VERSION ""

NS_ :

BS_:

BU_: data_logger drive_controller kart_machine_manager motec_ecu

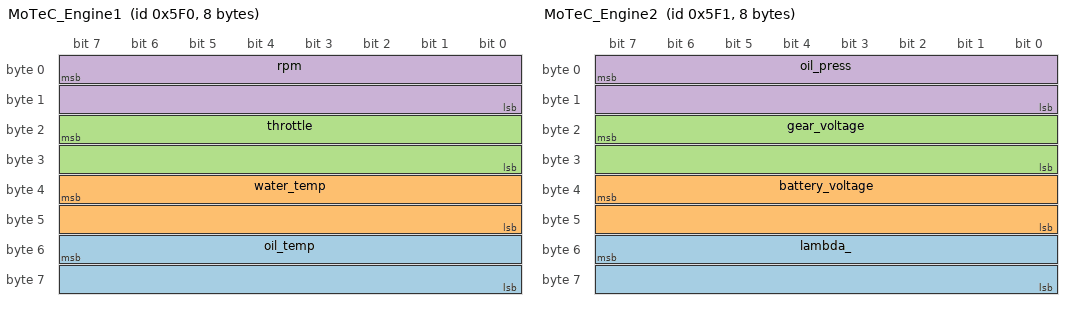
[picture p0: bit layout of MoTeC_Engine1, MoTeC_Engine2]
BO_ 1520 MoTeC_Engine1: 8 motec_ecu
 SG_ oil_temp : 55|16@0+ (0.1,0) [0|0] "degC"  kart_machine_manager
 SG_ water_temp : 39|16@0+ (0.1,0) [0|0] "degC"  kart_machine_manager
 SG_ throttle : 23|16@0+ (0.1,0) [0|0] "%"  kart_machine_manager
 SG_ rpm : 7|16@0+ (1,0) [0|0] "rpm"  kart_machine_manager

BO_ 1521 MoTeC_Engine2: 8 motec_ecu
 SG_ lambda_ : 55|16@0+ (0.001,0) [0|0] ""  kart_machine_manager
 SG_ battery_voltage : 39|16@0+ (0.01,0) [0|0] "V"  kart_machine_manager
 SG_ gear_voltage : 23|16@0+ (0.001,0) [0|0] "V"  kart_machine_manager
 SG_ oil_press : 7|16@0+ (0.1,0) [0|0] ""  kart_machine_manager

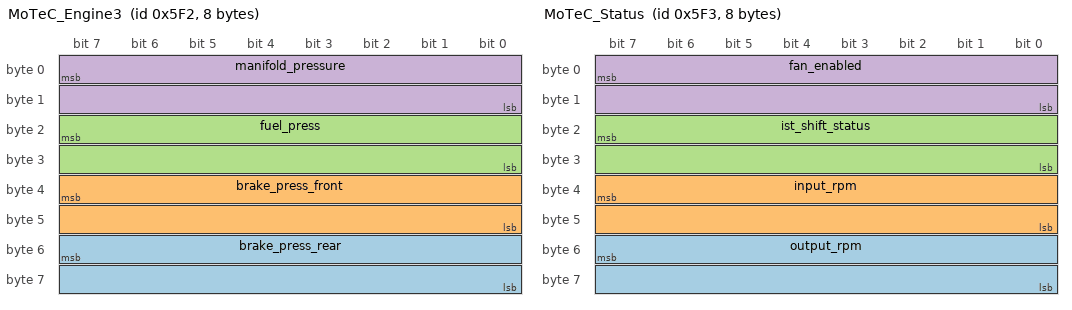
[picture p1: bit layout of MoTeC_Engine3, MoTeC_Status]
BO_ 1522 MoTeC_Engine3: 8 motec_ecu
 SG_ brake_press_rear : 55|16@0+ (0.1,0) [0|0] ""  kart_machine_manager
 SG_ brake_press_front : 39|16@0+ (0.1,0) [0|0] ""  kart_machine_manager
 SG_ fuel_press : 23|16@0+ (0.1,0) [0|0] ""  kart_machine_manager
 SG_ manifold_pressure : 7|16@0+ (0.1,0) [0|0] "kPa"  kart_machine_manager

BO_ 1523 MoTeC_Status: 8 motec_ecu
 SG_ output_rpm : 55|16@0+ (1,0) [0|0] "rpm"  kart_machine_manager
 SG_ input_rpm : 39|16@0+ (1,0) [0|0] "rpm"  kart_machine_manager
 SG_ ist_shift_status : 23|16@0+ (1,0) [0|0] ""  kart_machine_manager
 SG_ fan_enabled : 7|16@0+ (1,0) [0|0] ""  kart_machine_manager

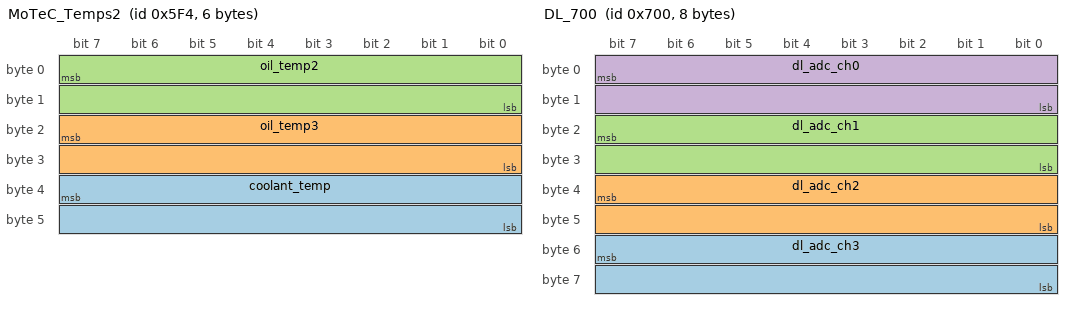
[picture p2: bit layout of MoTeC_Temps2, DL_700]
BO_ 1524 MoTeC_Temps2: 6 motec_ecu
 SG_ coolant_temp : 39|16@0+ (0.1,0) [0|0] "degC"  kart_machine_manager
 SG_ oil_temp3 : 23|16@0+ (0.1,0) [0|0] "degC"  kart_machine_manager
 SG_ oil_temp2 : 7|16@0+ (0.1,0) [0|0] "degC"  kart_machine_manager

BO_ 1536 DC_GyroXY: 8 drive_controller
 SG_ gyro_y : 32|32@1+ (1,0) [0|0] "dps" Vector__XXX
 SG_ gyro_x : 0|32@1+ (1,0) [0|0] "dps" Vector__XXX

BO_ 1537 DC_GyroZGear: 5 drive_controller
 SG_ gear : 32|8@1+ (1,0) [0|0] "" Vector__XXX
 SG_ gyro_z : 0|32@1+ (1,0) [0|0] "dps" Vector__XXX

BO_ 1538 DC_AccelXY: 8 drive_controller
 SG_ accel_y : 32|32@1+ (1,0) [0|0] "mg" Vector__XXX
 SG_ accel_x : 0|32@1+ (1,0) [0|0] "mg" Vector__XXX

BO_ 1539 DC_AccelZ: 4 drive_controller
 SG_ accel_z : 0|32@1+ (1,0) [0|0] "mg" Vector__XXX

BO_ 1792 DL_700: 8 data_logger
 SG_ dl_adc_ch3 : 55|16@0+ (7.8125e-05,0) [0|0] "V"  kart_machine_manager
 SG_ dl_adc_ch2 : 39|16@0+ (7.8125e-05,0) [0|0] "V"  kart_machine_manager
 SG_ dl_adc_ch1 : 23|16@0+ (7.8125e-05,0) [0|0] "V"  kart_machine_manager
 SG_ dl_adc_ch0 : 7|16@0+ (7.8125e-05,0) [0|0] "V"  kart_machine_manager

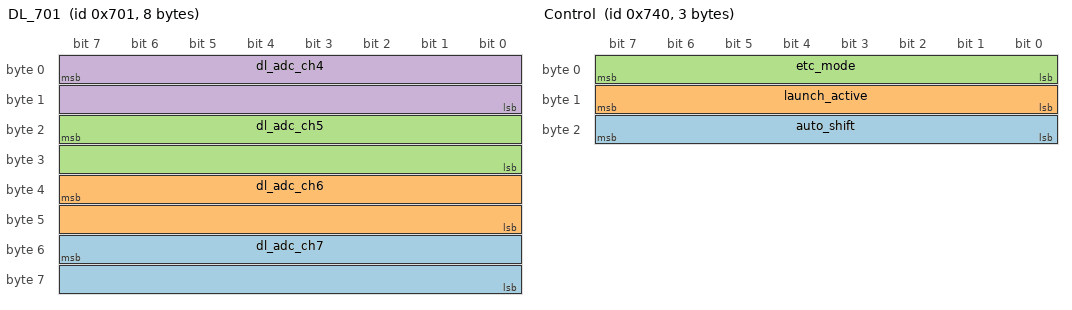
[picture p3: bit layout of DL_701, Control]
BO_ 1793 DL_701: 8 data_logger
 SG_ dl_adc_ch7 : 55|16@0+ (7.8125e-05,0) [0|0] "V"  kart_machine_manager
 SG_ dl_adc_ch6 : 39|16@0+ (7.8125e-05,0) [0|0] "V"  kart_machine_manager
 SG_ dl_adc_ch5 : 23|16@0+ (7.8125e-05,0) [0|0] "V"  kart_machine_manager
 SG_ dl_adc_ch4 : 7|16@0+ (7.8125e-05,0) [0|0] "V"  kart_machine_manager

BO_ 1856 Control: 3 drive_controller
 SG_ auto_shift : 16|8@1+ (1,0) [0|0] ""  kart_machine_manager
 SG_ launch_active : 8|8@1+ (1,0) [0|0] ""  kart_machine_manager
 SG_ etc_mode : 0|8@1+ (1,0) [0|0] ""  kart_machine_manager

CM_ BU_ data_logger "センサ送信 (i.MX8MM Cortex-M4)。ADS8688 ADC 8ch。";
CM_ BU_ drive_controller "駆動系ECU (Teensy 4.1)。ETC/オートシフタ/ローンチ制御。IMU (IAM-20680HP)+ギア、および制御入力状態(Control 0x740)を送信。";
CM_ BU_ motec_ecu "[外部ノード] MoTeC エンジンECU（外部）。エンジンデータを送信、kart-machine-manager が受信。";
CM_ SG_ 1521 lambda_ "表示側は未デコード";
CM_ SG_ 1522 manifold_pressure "表示側は未デコード";
CM_ SG_ 1523 output_rpm "表示側未デコード";
CM_ SG_ 1523 input_rpm "表示側未デコード";
CM_ SG_ 1523 ist_shift_status "(istUp,istDown): 0=なし,1=DOWN,2=UP,3=両方。表示側未デコード";
CM_ SG_ 1523 fan_enabled "表示側は下位バイト(data[1])をbool化";
CM_ BO_ 1524 "表示デコードなし・UDP転送のみ";
CM_ SG_ 1537 gear "0xFF=不明, 0=N, 1-6=段";
CM_ BO_ 1538 "単位要確認: 旧実装はヘッダm/s²・実データmg（can-spec.md 注意点4）。IAM-20680HP 移行実装時に単位を確定させること";
CM_ BO_ 1792 "data-logger 生バッファ byte 0-7（再構成の一部）";
CM_ BO_ 1793 "data-logger 生バッファ byte 8-15（再構成の一部）";
CM_ BO_ 1856 "制御信号フレーム (制御ID帯 0x740〜の先頭)。drive-controller が GPIO 制御入力状態を送信。byte0=ETCモード, byte1=launch, byte2=auto-shift。受信側は200ms途絶でフェイルセーフ。";
CM_ SG_ 1856 auto_shift "0x01=オート(ON)、その他=マニュアル(OFF)。200ms途絶→manual";
CM_ SG_ 1856 launch_active "0x01=active、その他=inactive。200ms途絶→inactive。通常ビルドではFSM無効";
CM_ SG_ 1856 etc_mode "0=未指定(無視・現モード維持)。200ms途絶→NORMAL(MOTOR_OFFはラッチ)";
BA_DEF_ BO_  "GenMsgCycleTime" INT 0 65535;
BA_DEF_DEF_  "GenMsgCycleTime" 0;
BA_ "GenMsgCycleTime" BO_ 1536 16;
BA_ "GenMsgCycleTime" BO_ 1537 16;
BA_ "GenMsgCycleTime" BO_ 1538 16;
BA_ "GenMsgCycleTime" BO_ 1539 16;
BA_ "GenMsgCycleTime" BO_ 1792 33;
BA_ "GenMsgCycleTime" BO_ 1793 33;
BA_ "GenMsgCycleTime" BO_ 1856 16;
VAL_ 1523 ist_shift_status 0 "NONE" 1 "DOWN" 2 "UP" 3 "BOTH" ;
VAL_ 1523 fan_enabled 0 "OFF" 1 "ON" ;
VAL_ 1856 auto_shift 0 "MANUAL" 1 "AUTO" ;
VAL_ 1856 launch_active 0 "INACTIVE" 1 "ACTIVE" ;
VAL_ 1856 etc_mode 1 "CALIB" 2 "NORMAL" 3 "RESTRICTED" 4 "MOTOR_OFF" ;
SIG_VALTYPE_ 1536 gyro_x : 1;
SIG_VALTYPE_ 1536 gyro_y : 1;
SIG_VALTYPE_ 1537 gyro_z : 1;
SIG_VALTYPE_ 1538 accel_x : 1;
SIG_VALTYPE_ 1538 accel_y : 1;
SIG_VALTYPE_ 1539 accel_z : 1;
